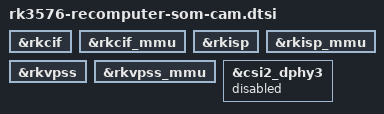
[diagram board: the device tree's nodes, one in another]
// SPDX-License-Identifier: (GPL-2.0+ OR MIT)
/*
 * reComputer RK3576 Module IO Board, camera media infrastructure
 * shared by the cam0 (I2C5) and cam1 (I2C6) links: CIF/ISP/VPSS
 * controllers and their IOMMUs.
 *
 * Copyright (c) 2024 Luckfox Technology Co., Ltd.
 * Copyright (c) 2026 Seeed Studio
 */

&rkcif {
	status = "okay";
};

&rkcif_mmu {
	status = "okay";
};

&rkisp {
	status = "okay";
};

&rkisp_mmu {
	status = "okay";
};

&rkvpss {
	status = "okay";
};

&rkvpss_mmu {
	status = "okay";
};

&csi2_dphy3 {
    status = "disabled";
};
